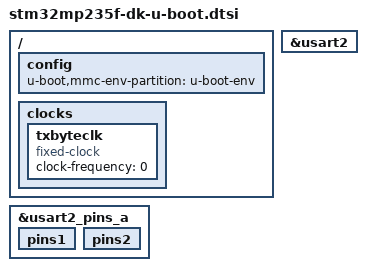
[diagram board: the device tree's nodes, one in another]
// SPDX-License-Identifier: GPL-2.0-or-later OR BSD-3-Clause
/*
 * Copyright (C) STMicroelectronics 2024 - All Rights Reserved
 */

#include "stm32mp23-u-boot.dtsi"

/ {
	config {
		u-boot,mmc-env-partition = "u-boot-env";
	};

	clocks {
		txbyteclk {
			#clock-cells = <0>;
			compatible = "fixed-clock";
			clock-frequency = <0>;
		};
	};
};

&usart2 {
	bootph-all;
};

&usart2_pins_a {
	bootph-all;
	pins1 {
		bootph-all;
	};
	pins2 {
		bootph-all;
	};
};
